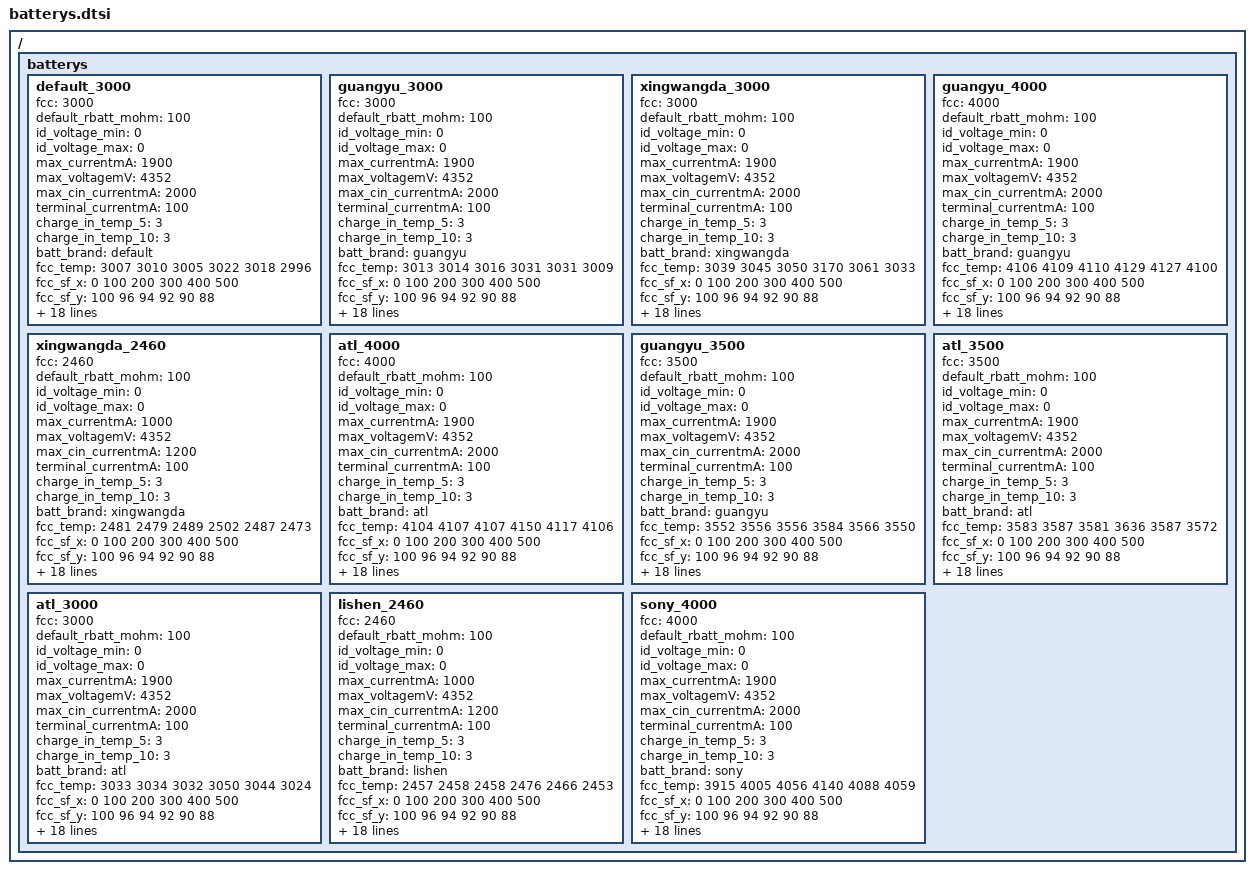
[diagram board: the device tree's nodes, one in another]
/* DO NOT EDIT - Automatically generated by python */
/ {
	batterys:batterys {
		default_3000:default_3000 {
			fcc = <3000>;
			default_rbatt_mohm = <100>;
			id_voltage_min = <0>;
			id_voltage_max = <0>;
			max_currentmA = <1900>;
			max_voltagemV = <4352>;
			max_cin_currentmA = <2000>;
			terminal_currentmA = <100>;
			charge_in_temp_5 = <3>;
			charge_in_temp_10 = <3>;
			batt_brand = "default";
			fcc_temp = <3007 3010 3005 3022 3018 2996>;
			fcc_sf_x = <0 100 200 300 400 500>;
			fcc_sf_y = <100 96 94 92 90 88>;
			fcc_sf_cols = <6>;
			pc_sf_rows = <1>;
			pc_sf_cols = <1>;
			pc_sf_row_entries = <0>;
			pc_sf_percent = <100>;
			pc_sf_sf = <100>;
			rbatt_sf_rows = <28>;
			rbatt_sf_cols = <6>;
			rbatt_sf_percent = <100 95 90 85 80 75 70 65 60 55 50 45 40 35 30 25 20 15 10 9 8 7 6 5 4 3 2 1>;
			rbatt_sf_sf = <
			               1971 888 459 150 121 112
			               1970 888 459 150 121 112
			               1839 913 472 152 123 113
			               1713 920 490 156 125 115
			               1676 943 504 161 128 116
			               1543 895 532 170 132 118
			               1517 837 489 181 137 121
			               1515 831 470 199 148 127
			               1516 824 448 200 160 137
			               1531 823 437 155 129 116
			               1611 847 434 150 123 114
			               1714 921 422 151 124 115
			               1830 1023 448 155 128 117
			               1954 1148 499 158 134 120
			               2083 1284 576 159 132 122
			               2230 1422 664 157 125 114
			               2410 1589 766 154 122 113
			               2657 1792 883 159 123 113
			               3658 1996 983 161 128 117
			               4481 2141 924 161 129 119
			               4966 2392 991 159 127 116
			               5434 2660 1095 166 127 116
			               5970 2933 1229 168 130 118
			               6541 3252 1382 172 129 118
			               7189 3594 1509 175 129 117
			               7980 3994 1669 183 132 119
			               8915 4511 1946 202 136 120
			               10198 5252 2365 279 143 122
			              >;
			pc_temp_ocv_rows = <29>;
			pc_temp_ocv_cols = <6>;
			pc_temp_ocv_percent = <100 95 90 85 80 75 70 65 60 55 50 45 40 35 30 25 20 15 10 9 8 7 6 5 4 3 2 1>;
			pc_temp_ocv_ocv = <
			                   4326 4325 4322 4317 4311 4305
			                   4224 4239 4246 4254 4249 4245
			                   4156 4178 4186 4196 4193 4189
			                   4090 4121 4132 4142 4138 4134
			                   4041 4073 4082 4090 4086 4083
			                   3967 4011 4034 4042 4038 4035
			                   3917 3951 3976 3997 3994 3991
			                   3878 3907 3929 3957 3955 3952
			                   3843 3868 3885 3914 3915 3914
			                   3815 3833 3849 3865 3865 3863
			                   3801 3808 3821 3835 3835 3834
			                   3788 3796 3797 3813 3812 3812
			                   3774 3786 3785 3794 3794 3793
			                   3760 3776 3777 3779 3780 3778
			                   3746 3761 3768 3767 3765 3762
			                   3732 3740 3753 3754 3747 3737
			                   3716 3720 3730 3734 3726 3716
			                   3699 3702 3700 3705 3699 3688
			                   3671 3684 3677 3680 3674 3664
			                   3662 3677 3673 3679 3672 3662
			                   3653 3671 3669 3677 3671 3660
			                   3640 3664 3664 3673 3668 3657
			                   3626 3654 3658 3667 3663 3652
			                   3606 3637 3645 3650 3650 3638
			                   3578 3609 3618 3611 3614 3604
			                   3540 3566 3571 3554 3560 3553
			                   3482 3500 3502 3478 3490 3486
			                   3389 3399 3403 3363 3387 3387
			                   3200 3200 3200 3200 3200 3200
			                  >;
		};
		guangyu_3000:guangyu_3000 {
			fcc = <3000>;
			default_rbatt_mohm = <100>;
			id_voltage_min = <0>;
			id_voltage_max = <0>;
			max_currentmA = <1900>;
			max_voltagemV = <4352>;
			max_cin_currentmA = <2000>;
			terminal_currentmA = <100>;
			charge_in_temp_5 = <3>;
			charge_in_temp_10 = <3>;
			batt_brand = "guangyu";
			fcc_temp = <3013 3014 3016 3031 3031 3009>;
			fcc_sf_x = <0 100 200 300 400 500>;
			fcc_sf_y = <100 96 94 92 90 88>;
			fcc_sf_cols = <6>;
			pc_sf_rows = <1>;
			pc_sf_cols = <1>;
			pc_sf_row_entries = <0>;
			pc_sf_percent = <100>;
			pc_sf_sf = <100>;
			rbatt_sf_rows = <28>;
			rbatt_sf_cols = <6>;
			rbatt_sf_percent = <100 95 90 85 80 75 70 65 60 55 50 45 40 35 30 25 20 15 10 9 8 7 6 5 4 3 2 1>;
			rbatt_sf_sf = <
			               2296 1218 555 154 124 116
			               2295 1218 555 154 124 116
			               2157 1236 570 155 125 116
			               2015 1213 583 159 127 118
			               1974 1232 604 164 130 119
			               1760 1140 645 180 140 121
			               1717 1075 529 180 138 124
			               1715 1101 533 202 149 131
			               1704 1108 532 184 149 133
			               1699 1122 537 153 126 118
			               1762 1161 547 151 124 117
			               1829 1236 555 153 126 118
			               1900 1319 601 158 129 120
			               1981 1414 659 162 134 123
			               2069 1514 725 162 132 119
			               2169 1620 792 159 125 117
			               2287 1768 875 158 125 117
			               2447 1942 988 161 126 118
			               2777 1853 1035 163 129 120
			               3036 1627 929 163 128 120
			               3289 1766 978 160 129 118
			               3533 1910 1057 163 128 120
			               3803 2045 1140 162 127 121
			               4109 2198 1212 160 126 119
			               4433 2395 1256 164 129 119
			               4864 2650 1353 170 130 120
			               5383 2992 1559 182 131 122
			               6090 3480 1878 216 139 127
			              >;
			pc_temp_ocv_rows = <29>;
			pc_temp_ocv_cols = <6>;
			pc_temp_ocv_percent = <100 95 90 85 80 75 70 65 60 55 50 45 40 35 30 25 20 15 10 9 8 7 6 5 4 3 2 1>;
			pc_temp_ocv_ocv = <
			                   4331 4329 4327 4324 4318 4313
			                   4236 4244 4252 4261 4258 4254
			                   4170 4184 4194 4205 4202 4199
			                   4109 4124 4141 4152 4148 4145
			                   4068 4079 4093 4099 4096 4094
			                   3976 4004 4048 4060 4052 4045
			                   3925 3941 3963 3991 3995 4001
			                   3887 3905 3922 3958 3960 3960
			                   3850 3868 3886 3913 3913 3913
			                   3816 3835 3852 3868 3868 3868
			                   3798 3810 3825 3840 3839 3839
			                   3784 3796 3801 3818 3817 3817
			                   3771 3783 3788 3800 3799 3798
			                   3759 3773 3777 3784 3784 3783
			                   3748 3759 3767 3769 3767 3761
			                   3736 3741 3752 3754 3746 3735
			                   3722 3725 3732 3734 3726 3715
			                   3705 3710 3706 3708 3701 3689
			                   3678 3692 3689 3688 3681 3671
			                   3669 3686 3685 3687 3680 3669
			                   3659 3679 3680 3685 3678 3667
			                   3645 3671 3673 3681 3675 3664
			                   3628 3656 3661 3672 3666 3653
			                   3607 3634 3640 3645 3640 3626
			                   3576 3602 3605 3601 3598 3585
			                   3535 3556 3553 3546 3545 3533
			                   3477 3492 3484 3474 3475 3465
			                   3388 3395 3385 3370 3375 3367
			                   3200 3200 3200 3200 3200 3200
			                  >;
		};
		xingwangda_3000:xingwangda_3000 {
			fcc = <3000>;
			default_rbatt_mohm = <100>;
			id_voltage_min = <0>;
			id_voltage_max = <0>;
			max_currentmA = <1900>;
			max_voltagemV = <4352>;
			max_cin_currentmA = <2000>;
			terminal_currentmA = <100>;
			charge_in_temp_5 = <3>;
			charge_in_temp_10 = <3>;
			batt_brand = "xingwangda";
			fcc_temp = <3039 3045 3050 3170 3061 3033>;
			fcc_sf_x = <0 100 200 300 400 500>;
			fcc_sf_y = <100 96 94 92 90 88>;
			fcc_sf_cols = <6>;
			pc_sf_rows = <1>;
			pc_sf_cols = <1>;
			pc_sf_row_entries = <0>;
			pc_sf_percent = <100>;
			pc_sf_sf = <100>;
			rbatt_sf_rows = <28>;
			rbatt_sf_cols = <6>;
			rbatt_sf_percent = <100 95 90 85 80 75 70 65 60 55 50 45 40 35 30 25 20 15 10 9 8 7 6 5 4 3 2 1>;
			rbatt_sf_sf = <
			               2150 1340 721 149 116 105
			               2147 1338 720 149 116 105
			               1947 1200 694 155 120 107
			               1863 1117 674 161 124 111
			               1844 1107 672 167 130 114
			               1812 1106 678 175 135 117
			               1823 1095 677 185 140 120
			               1844 1111 673 199 148 125
			               1880 1123 670 199 154 130
			               1930 1150 678 169 135 116
			               1997 1193 708 154 121 109
			               2076 1251 756 158 126 112
			               2160 1321 818 165 133 116
			               2248 1400 889 172 137 120
			               2345 1483 963 182 135 119
			               2459 1570 1044 188 131 112
			               2618 1661 1125 188 132 111
			               2865 1787 1224 185 134 112
			               6112 2810 1460 197 140 118
			               6697 3079 1592 202 141 117
			               7275 3352 1729 206 143 117
			               7819 3647 1884 213 144 119
			               8352 3959 2048 218 144 120
			               8890 4232 2199 221 148 123
			               9495 4608 2386 238 156 128
			               10120 5012 2622 263 162 125
			               10828 5562 2991 299 167 125
			               11962 6368 3532 500 186 134
			              >;
			pc_temp_ocv_rows = <29>;
			pc_temp_ocv_cols = <6>;
			pc_temp_ocv_percent = <100 95 90 85 80 75 70 65 60 55 50 45 40 35 30 25 20 15 10 9 8 7 6 5 4 3 2 1>;
			pc_temp_ocv_ocv = <
			                   4329 4327 4324 4349 4314 4308
			                   4239 4246 4248 4288 4254 4250
			                   4170 4181 4187 4229 4198 4195
			                   4111 4123 4132 4173 4144 4141
			                   4054 4073 4081 4118 4093 4091
			                   3984 4017 4030 4067 4045 4042
			                   3935 3958 3978 4017 3998 3998
			                   3893 3915 3930 3971 3959 3958
			                   3860 3875 3887 3927 3918 3918
			                   3835 3844 3851 3880 3871 3870
			                   3817 3821 3824 3844 3837 3838
			                   3802 3805 3806 3819 3814 3815
			                   3787 3792 3792 3799 3796 3795
			                   3774 3780 3780 3782 3780 3779
			                   3759 3766 3767 3770 3764 3760
			                   3742 3751 3753 3756 3747 3736
			                   3724 3729 3732 3733 3722 3711
			                   3700 3704 3705 3692 3691 3679
			                   3669 3679 3677 3679 3671 3662
			                   3659 3672 3671 3677 3670 3660
			                   3648 3663 3664 3673 3667 3657
			                   3634 3651 3655 3668 3662 3652
			                   3615 3636 3642 3656 3651 3639
			                   3590 3611 3621 3626 3623 3610
			                   3560 3578 3587 3583 3583 3571
			                   3518 3533 3536 3527 3532 3520
			                   3458 3468 3464 3454 3463 3451
			                   3377 3375 3358 3358 3365 3354
			                   3200 3200 3200 3200 3200 3200
			                  >;
		};
		guangyu_4000:guangyu_4000 {
			fcc = <4000>;
			default_rbatt_mohm = <100>;
			id_voltage_min = <0>;
			id_voltage_max = <0>;
			max_currentmA = <1900>;
			max_voltagemV = <4352>;
			max_cin_currentmA = <2000>;
			terminal_currentmA = <100>;
			charge_in_temp_5 = <3>;
			charge_in_temp_10 = <3>;
			batt_brand = "guangyu";
			fcc_temp = <4106 4109 4110 4129 4127 4100>;
			fcc_sf_x = <0 100 200 300 400 500>;
			fcc_sf_y = <100 96 94 92 90 88>;
			fcc_sf_cols = <6>;
			pc_sf_rows = <1>;
			pc_sf_cols = <1>;
			pc_sf_row_entries = <0>;
			pc_sf_percent = <100>;
			pc_sf_sf = <100>;
			rbatt_sf_rows = <28>;
			rbatt_sf_cols = <6>;
			rbatt_sf_percent = <100 95 90 85 80 75 70 65 60 55 50 45 40 35 30 25 20 15 10 9 8 7 6 5 4 3 2 1>;
			rbatt_sf_sf = <
			               1565 695 344 128 112 107
			               1563 696 344 128 112 107
			               1495 704 349 129 112 108
			               1420 705 353 132 114 108
			               1398 721 361 135 115 109
			               1251 720 400 144 120 111
			               1216 625 342 147 122 113
			               1213 638 332 159 129 117
			               1210 640 332 145 129 119
			               1231 644 322 127 114 108
			               1266 664 322 126 112 108
			               1312 706 330 128 113 108
			               1366 759 342 131 115 110
			               1424 823 368 133 118 113
			               1486 895 401 132 116 111
			               1563 982 441 130 112 108
			               1665 1103 485 130 113 108
			               1802 1289 545 130 114 108
			               2126 1109 434 129 114 112
			               2290 1208 445 130 115 110
			               2430 1312 474 132 116 110
			               2575 1441 511 132 117 114
			               2729 1575 559 133 117 112
			               2869 1704 602 132 115 110
			               3040 1819 649 133 115 110
			               3325 1917 718 135 117 112
			               3667 2016 797 155 119 114
			               4315 2465 877 342 165 133
			              >;
			pc_temp_ocv_rows = <29>;
			pc_temp_ocv_cols = <6>;
			pc_temp_ocv_percent = <100 95 90 85 80 75 70 65 60 55 50 45 40 35 30 25 20 15 10 9 8 7 6 5 4 3 2 1>;
			pc_temp_ocv_ocv = <
			                   4333 4331 4330 4327 4322 4316
			                   4238 4251 4257 4265 4262 4257
			                   4173 4192 4201 4208 4205 4202
			                   4112 4137 4148 4154 4151 4147
			                   4070 4090 4099 4103 4099 4095
			                   3980 4035 4055 4058 4050 4046
			                   3928 3950 3972 3995 3998 4001
			                   3891 3911 3927 3959 3961 3959
			                   3857 3874 3892 3912 3915 3914
			                   3833 3842 3857 3869 3868 3868
			                   3814 3818 3829 3840 3840 3839
			                   3799 3803 3807 3818 3817 3817
			                   3786 3790 3792 3800 3799 3798
			                   3773 3778 3781 3784 3784 3782
			                   3760 3764 3772 3769 3765 3760
			                   3747 3747 3759 3752 3744 3734
			                   3735 3729 3739 3732 3725 3713
			                   3721 3714 3713 3705 3699 3689
			                   3700 3695 3691 3688 3681 3670
			                   3696 3691 3688 3686 3680 3669
			                   3690 3686 3686 3684 3678 3667
			                   3682 3681 3681 3681 3675 3665
			                   3670 3672 3673 3670 3667 3656
			                   3651 3656 3655 3641 3642 3633
			                   3621 3628 3623 3598 3602 3594
			                   3578 3585 3577 3541 3550 3544
			                   3512 3517 3513 3466 3481 3478
			                   3409 3413 3417 3362 3383 3384
			                   3200 3200 3200 3200 3200 3200
			                  >;
		};
		xingwangda_2460:xingwangda_2460 {
			fcc = <2460>;
			default_rbatt_mohm = <100>;
			id_voltage_min = <0>;
			id_voltage_max = <0>;
			max_currentmA = <1000>;
			max_voltagemV = <4352>;
			max_cin_currentmA = <1200>;
			terminal_currentmA = <100>;
			charge_in_temp_5 = <3>;
			charge_in_temp_10 = <3>;
			batt_brand = "xingwangda";
			fcc_temp = <2481 2479 2489 2502 2487 2473>;
			fcc_sf_x = <0 100 200 300 400 500>;
			fcc_sf_y = <100 96 94 92 90 88>;
			fcc_sf_cols = <6>;
			pc_sf_rows = <1>;
			pc_sf_cols = <1>;
			pc_sf_row_entries = <0>;
			pc_sf_percent = <100>;
			pc_sf_sf = <100>;
			rbatt_sf_rows = <28>;
			rbatt_sf_cols = <6>;
			rbatt_sf_percent = <100 95 90 85 80 75 70 65 60 55 50 45 40 35 30 25 20 15 10 9 8 7 6 5 4 3 2 1>;
			rbatt_sf_sf = <
			               3248 2075 1055 235 151 131
			               3247 2075 1055 235 151 131
			               2997 1985 1040 239 153 131
			               2843 1898 1019 243 156 134
			               2704 1860 1050 250 160 136
			               2535 1659 1002 270 167 139
			               2514 1648 908 272 175 143
			               2502 1646 912 297 186 151
			               2503 1647 882 278 206 166
			               2518 1641 880 229 156 135
			               2550 1669 888 224 150 132
			               2601 1701 904 226 153 134
			               2671 1760 953 232 158 137
			               2759 1821 1015 238 164 143
			               2874 1897 1093 240 162 142
			               3026 2005 1172 242 155 135
			               3093 2156 1267 246 153 133
			               1808 2375 1388 251 155 133
			               4307 2722 1511 254 159 136
			               6006 2925 1316 250 163 140
			               6516 3169 1419 252 161 139
			               6828 3408 1524 258 159 138
			               7159 3645 1678 257 158 138
			               7408 3869 1794 257 157 137
			               7625 4088 1812 260 156 136
			               8299 4268 1901 268 159 136
			               9290 4549 2002 292 165 137
			               11334 5087 2295 547 175 168
			              >;
			pc_temp_ocv_rows = <29>;
			pc_temp_ocv_cols = <6>;
			pc_temp_ocv_percent = <100 95 90 85 80 75 70 65 60 55 50 45 40 35 30 25 20 15 10 9 8 7 6 5 4 3 2 1>;
			pc_temp_ocv_ocv = <
			                   4315 4313 4316 4307 4300 4294
			                   4222 4228 4237 4242 4239 4235
			                   4154 4167 4178 4186 4183 4180
			                   4103 4112 4123 4134 4130 4127
			                   4043 4069 4082 4083 4080 4077
			                   3970 3982 4022 4040 4034 4030
			                   3928 3939 3956 3981 3990 3988
			                   3891 3903 3921 3953 3952 3950
			                   3859 3871 3881 3908 3914 3913
			                   3834 3842 3849 3862 3863 3863
			                   3814 3820 3823 3833 3835 3834
			                   3796 3801 3805 3812 3813 3813
			                   3781 3787 3792 3794 3796 3795
			                   3767 3771 3782 3780 3782 3781
			                   3755 3757 3771 3768 3767 3764
			                   3743 3742 3755 3756 3751 3741
			                   3730 3730 3736 3739 3732 3720
			                   3722 3717 3715 3711 3705 3693
			                   3681 3698 3703 3689 3681 3672
			                   3679 3692 3698 3687 3680 3670
			                   3673 3685 3694 3686 3679 3669
			                   3663 3677 3691 3684 3677 3667
			                   3649 3666 3687 3679 3674 3663
			                   3623 3650 3677 3664 3662 3650
			                   3578 3627 3650 3625 3630 3616
			                   3524 3589 3606 3569 3578 3564
			                   3465 3531 3537 3489 3507 3494
			                   3378 3436 3429 3372 3399 3389
			                   3200 3200 3200 3200 3200 3200
			                  >;
		};
		atl_4000:atl_4000 {
			fcc = <4000>;
			default_rbatt_mohm = <100>;
			id_voltage_min = <0>;
			id_voltage_max = <0>;
			max_currentmA = <1900>;
			max_voltagemV = <4352>;
			max_cin_currentmA = <2000>;
			terminal_currentmA = <100>;
			charge_in_temp_5 = <3>;
			charge_in_temp_10 = <3>;
			batt_brand = "atl";
			fcc_temp = <4104 4107 4107 4150 4117 4106>;
			fcc_sf_x = <0 100 200 300 400 500>;
			fcc_sf_y = <100 96 94 92 90 88>;
			fcc_sf_cols = <6>;
			pc_sf_rows = <1>;
			pc_sf_cols = <1>;
			pc_sf_row_entries = <0>;
			pc_sf_percent = <100>;
			pc_sf_sf = <100>;
			rbatt_sf_rows = <28>;
			rbatt_sf_cols = <6>;
			rbatt_sf_percent = <100 95 90 85 80 75 70 65 60 55 50 45 40 35 30 25 20 15 10 9 8 7 6 5 4 3 2 1>;
			rbatt_sf_sf = <
			               1638 779 406 150 124 116
			               1635 780 406 150 124 116
			               1515 790 415 152 124 117
			               1434 791 424 155 127 118
			               1370 791 437 161 129 119
			               1295 741 441 168 131 120
			               1283 732 421 179 137 124
			               1276 722 407 186 145 128
			               1281 709 393 175 152 133
			               1305 718 385 155 136 127
			               1354 746 383 149 125 118
			               1426 798 383 149 126 118
			               1513 870 402 151 128 120
			               1612 957 439 153 131 122
			               1720 1060 495 154 130 122
			               1837 1183 567 153 126 117
			               1986 1320 652 153 125 117
			               2209 1470 771 155 127 118
			               3853 1617 747 153 128 119
			               4241 1726 806 155 128 120
			               4675 1864 894 159 129 121
			               5150 1933 1014 162 131 122
			               5702 2318 1182 166 132 124
			               6282 2789 1350 172 133 123
			               6851 3240 1517 175 133 122
			               7837 3723 1611 182 138 126
			               9114 4367 1702 222 185 176
			               12396 5272 2362 401 262 184
			              >;
			pc_temp_ocv_rows = <29>;
			pc_temp_ocv_cols = <6>;
			pc_temp_ocv_percent = <100 95 90 85 80 75 70 65 60 55 50 45 40 35 30 25 20 15 10 9 8 7 6 5 4 3 2 1>;
			pc_temp_ocv_ocv = <
			                   4324 4323 4321 4323 4312 4308
			                   4218 4233 4241 4255 4247 4244
			                   4144 4167 4179 4197 4189 4187
			                   4083 4109 4124 4142 4134 4132
			                   4021 4056 4073 4090 4083 4080
			                   3953 3990 4020 4041 4035 4032
			                   3908 3943 3968 3996 3991 3989
			                   3870 3899 3922 3953 3952 3949
			                   3840 3858 3880 3907 3912 3911
			                   3819 3827 3846 3865 3866 3867
			                   3805 3808 3817 3835 3833 3832
			                   3794 3796 3797 3811 3811 3809
			                   3782 3786 3785 3793 3793 3791
			                   3771 3774 3776 3778 3778 3776
			                   3758 3760 3766 3766 3763 3758
			                   3742 3743 3751 3753 3746 3736
			                   3725 3726 3728 3734 3727 3715
			                   3708 3709 3698 3702 3697 3686
			                   3689 3687 3670 3678 3671 3661
			                   3683 3682 3666 3676 3669 3659
			                   3676 3678 3662 3673 3667 3657
			                   3669 3664 3659 3668 3663 3653
			                   3661 3653 3655 3661 3658 3648
			                   3643 3639 3647 3644 3644 3634
			                   3600 3613 3626 3608 3611 3599
			                   3545 3567 3581 3551 3558 3547
			                   3476 3500 3504 3475 3491 3482
			                   3375 3398 3408 3370 3396 3383
			                   3200 3200 3200 3200 3200 3200
			                  >;
		};
		guangyu_3500:guangyu_3500 {
			fcc = <3500>;
			default_rbatt_mohm = <100>;
			id_voltage_min = <0>;
			id_voltage_max = <0>;
			max_currentmA = <1900>;
			max_voltagemV = <4352>;
			max_cin_currentmA = <2000>;
			terminal_currentmA = <100>;
			charge_in_temp_5 = <3>;
			charge_in_temp_10 = <3>;
			batt_brand = "guangyu";
			fcc_temp = <3552 3556 3556 3584 3566 3550>;
			fcc_sf_x = <0 100 200 300 400 500>;
			fcc_sf_y = <100 96 94 92 90 88>;
			fcc_sf_cols = <6>;
			pc_sf_rows = <1>;
			pc_sf_cols = <1>;
			pc_sf_row_entries = <0>;
			pc_sf_percent = <100>;
			pc_sf_sf = <100>;
			rbatt_sf_rows = <28>;
			rbatt_sf_cols = <6>;
			rbatt_sf_percent = <100 95 90 85 80 75 70 65 60 55 50 45 40 35 30 25 20 15 10 9 8 7 6 5 4 3 2 1>;
			rbatt_sf_sf = <
			               1818 753 394 139 114 106
			               1817 753 394 139 114 107
			               1741 756 397 139 114 107
			               1650 755 404 140 115 107
			               1620 767 414 144 118 108
			               1443 769 452 152 122 109
			               1395 665 395 153 122 111
			               1392 673 388 169 129 115
			               1380 673 377 164 135 120
			               1389 671 365 137 117 109
			               1428 679 367 132 113 107
			               1475 711 375 133 114 107
			               1528 763 388 135 115 109
			               1587 820 417 138 119 111
			               1650 885 453 138 118 112
			               1722 960 495 135 112 107
			               1808 1050 544 135 113 106
			               1928 1196 603 136 113 106
			               2117 1008 490 136 115 106
			               2269 1063 489 136 115 108
			               2447 1135 511 138 115 109
			               2618 1226 534 138 115 110
			               2825 1335 581 138 116 110
			               3040 1457 626 138 114 108
			               3280 1585 658 140 115 109
			               3585 1742 700 147 117 110
			               4006 1979 790 240 120 109
			               4721 2391 1004 197 186 114
			              >;
			pc_temp_ocv_rows = <29>;
			pc_temp_ocv_cols = <6>;
			pc_temp_ocv_percent = <100 95 90 85 80 75 70 65 60 55 50 45 40 35 30 25 20 15 10 9 8 7 6 5 4 3 2 1>;
			pc_temp_ocv_ocv = <
			                   4329 4328 4325 4323 4317 4312
			                   4239 4251 4253 4260 4255 4252
			                   4176 4195 4197 4204 4199 4196
			                   4118 4143 4146 4150 4145 4142
			                   4078 4097 4099 4099 4094 4091
			                   3987 4044 4053 4055 4048 4043
			                   3934 3958 3973 3991 3994 3999
			                   3898 3921 3932 3959 3960 3958
			                   3863 3886 3896 3916 3918 3917
			                   3836 3854 3860 3870 3870 3869
			                   3820 3826 3832 3841 3840 3839
			                   3806 3808 3811 3818 3818 3817
			                   3793 3795 3794 3801 3800 3798
			                   3780 3784 3784 3786 3785 3783
			                   3766 3773 3775 3772 3769 3765
			                   3752 3759 3763 3756 3747 3736
			                   3738 3739 3745 3737 3728 3716
			                   3721 3718 3719 3712 3703 3692
			                   3698 3696 3694 3690 3682 3671
			                   3691 3692 3691 3688 3681 3670
			                   3683 3687 3688 3686 3679 3668
			                   3672 3682 3683 3683 3676 3665
			                   3657 3673 3676 3674 3669 3656
			                   3636 3656 3659 3650 3647 3633
			                   3603 3625 3626 3609 3607 3594
			                   3557 3576 3575 3555 3556 3543
			                   3491 3508 3507 3489 3488 3475
			                   3393 3411 3410 3383 3392 3376
			                   3200 3200 3200 3200 3200 3200
			                  >;
		};
		atl_3500:atl_3500 {
			fcc = <3500>;
			default_rbatt_mohm = <100>;
			id_voltage_min = <0>;
			id_voltage_max = <0>;
			max_currentmA = <1900>;
			max_voltagemV = <4352>;
			max_cin_currentmA = <2000>;
			terminal_currentmA = <100>;
			charge_in_temp_5 = <3>;
			charge_in_temp_10 = <3>;
			batt_brand = "atl";
			fcc_temp = <3583 3587 3581 3636 3587 3572>;
			fcc_sf_x = <0 100 200 300 400 500>;
			fcc_sf_y = <100 96 94 92 90 88>;
			fcc_sf_cols = <6>;
			pc_sf_rows = <1>;
			pc_sf_cols = <1>;
			pc_sf_row_entries = <0>;
			pc_sf_percent = <100>;
			pc_sf_sf = <100>;
			rbatt_sf_rows = <28>;
			rbatt_sf_cols = <6>;
			rbatt_sf_percent = <100 95 90 85 80 75 70 65 60 55 50 45 40 35 30 25 20 15 10 9 8 7 6 5 4 3 2 1>;
			rbatt_sf_sf = <
			               1689 710 398 142 110 97
			               1686 710 398 142 110 97
			               1567 726 409 146 111 99
			               1463 727 420 150 114 101
			               1438 729 429 157 117 102
			               1339 715 441 167 121 104
			               1323 660 414 177 126 108
			               1323 655 402 188 135 112
			               1319 649 389 175 145 119
			               1336 648 378 146 129 117
			               1388 654 375 140 111 100
			               1455 690 376 142 112 100
			               1538 754 385 144 115 103
			               1637 829 415 146 118 106
			               1751 920 461 147 118 106
			               1889 1026 524 147 113 98
			               2063 1168 604 147 111 98
			               2304 1381 714 148 112 99
			               4047 1630 678 146 113 101
			               4518 1817 729 148 115 102
			               4974 2037 784 152 116 103
			               5527 2281 888 157 117 104
			               6126 2591 1028 166 120 104
			               6817 2948 1196 173 122 105
			               7595 3330 1392 171 122 104
			               8534 3821 1629 186 123 105
			               9862 4511 1987 392 127 109
			               13656 5696 2716 228 239 113
			              >;
			pc_temp_ocv_rows = <29>;
			pc_temp_ocv_cols = <6>;
			pc_temp_ocv_percent = <100 95 90 85 80 75 70 65 60 55 50 45 40 35 30 25 20 15 10 9 8 7 6 5 4 3 2 1>;
			pc_temp_ocv_ocv = <
			                   4329 4328 4323 4329 4312 4308
			                   4231 4244 4247 4261 4249 4245
			                   4158 4181 4187 4203 4191 4189
			                   4091 4125 4131 4147 4136 4134
			                   4042 4072 4079 4094 4084 4082
			                   3969 4016 4026 4044 4036 4034
			                   3921 3954 3970 3997 3992 3990
			                   3881 3912 3926 3955 3953 3951
			                   3844 3874 3886 3910 3914 3913
			                   3816 3841 3851 3866 3869 3870
			                   3800 3813 3823 3836 3833 3833
			                   3786 3796 3801 3813 3811 3810
			                   3773 3785 3785 3794 3793 3792
			                   3759 3774 3776 3779 3778 3777
			                   3746 3760 3767 3766 3765 3761
			                   3731 3743 3755 3754 3749 3738
			                   3716 3722 3735 3737 3730 3717
			                   3696 3702 3705 3707 3699 3689
			                   3669 3679 3675 3680 3673 3662
			                   3662 3673 3671 3678 3671 3660
			                   3651 3668 3666 3674 3668 3658
			                   3640 3660 3661 3670 3665 3654
			                   3625 3651 3654 3664 3659 3649
			                   3606 3637 3642 3649 3646 3636
			                   3578 3610 3617 3615 3615 3602
			                   3536 3567 3573 3561 3563 3550
			                   3480 3500 3504 3499 3491 3480
			                   3389 3405 3410 3389 3395 3378
			                   3200 3200 3200 3200 3200 3200
			                  >;
		};
		atl_3000:atl_3000 {
			fcc = <3000>;
			default_rbatt_mohm = <100>;
			id_voltage_min = <0>;
			id_voltage_max = <0>;
			max_currentmA = <1900>;
			max_voltagemV = <4352>;
			max_cin_currentmA = <2000>;
			terminal_currentmA = <100>;
			charge_in_temp_5 = <3>;
			charge_in_temp_10 = <3>;
			batt_brand = "atl";
			fcc_temp = <3033 3034 3032 3050 3044 3024>;
			fcc_sf_x = <0 100 200 300 400 500>;
			fcc_sf_y = <100 96 94 92 90 88>;
			fcc_sf_cols = <6>;
			pc_sf_rows = <1>;
			pc_sf_cols = <1>;
			pc_sf_row_entries = <0>;
			pc_sf_percent = <100>;
			pc_sf_sf = <100>;
			rbatt_sf_rows = <28>;
			rbatt_sf_cols = <6>;
			rbatt_sf_percent = <100 95 90 85 80 75 70 65 60 55 50 45 40 35 30 25 20 15 10 9 8 7 6 5 4 3 2 1>;
			rbatt_sf_sf = <
			               1945 876 456 149 120 111
			               1943 876 456 149 120 111
			               1816 900 469 151 122 113
			               1692 905 486 156 124 114
			               1658 927 498 161 127 115
			               1524 882 528 171 131 118
			               1500 822 482 182 137 121
			               1498 817 464 200 148 127
			               1498 809 443 198 157 135
			               1515 808 434 156 131 118
			               1594 831 429 150 122 114
			               1696 903 419 151 123 115
			               1811 1002 443 155 127 117
			               1934 1124 492 158 133 120
			               2063 1255 565 159 131 121
			               2209 1393 652 156 124 114
			               2391 1560 750 154 122 113
			               2637 1768 870 159 122 113
			               4010 2024 909 160 126 116
			               4629 2200 906 161 126 116
			               5065 2432 973 159 126 115
			               5531 2680 1073 165 127 116
			               6025 2959 1196 169 129 118
			               6587 3266 1333 172 129 117
			               7217 3599 1471 178 129 118
			               7973 3995 1643 184 133 118
			               8932 4540 1942 261 145 125
			               10221 5278 2367 531 224 177
			              >;
			pc_temp_ocv_rows = <29>;
			pc_temp_ocv_cols = <6>;
			pc_temp_ocv_percent = <100 95 90 85 80 75 70 65 60 55 50 45 40 35 30 25 20 15 10 9 8 7 6 5 4 3 2 1>;
			pc_temp_ocv_ocv = <
			                   4328 4327 4324 4319 4313 4307
			                   4226 4240 4248 4255 4250 4246
			                   4157 4179 4188 4197 4193 4190
			                   4091 4122 4134 4142 4138 4135
			                   4042 4074 4083 4090 4086 4084
			                   3967 4013 4036 4042 4038 4035
			                   3918 3952 3976 3997 3994 3991
			                   3879 3908 3930 3957 3955 3952
			                   3843 3869 3886 3913 3915 3914
			                   3815 3834 3851 3865 3866 3865
			                   3801 3808 3822 3835 3835 3834
			                   3788 3796 3798 3813 3812 3812
			                   3774 3786 3785 3794 3794 3793
			                   3760 3776 3777 3779 3780 3778
			                   3746 3761 3768 3767 3765 3761
			                   3732 3740 3753 3753 3747 3737
			                   3716 3720 3730 3734 3726 3716
			                   3699 3703 3701 3704 3698 3688
			                   3672 3683 3677 3680 3674 3664
			                   3663 3677 3673 3679 3672 3662
			                   3654 3671 3669 3677 3670 3660
			                   3642 3664 3665 3673 3668 3657
			                   3627 3655 3659 3666 3662 3652
			                   3607 3638 3645 3648 3649 3638
			                   3580 3611 3619 3608 3613 3603
			                   3541 3568 3574 3550 3559 3551
			                   3487 3506 3508 3476 3488 3482
			                   3400 3413 3414 3373 3387 3384
			                   3200 3200 3200 3200 3200 3200
			                  >;
		};
		lishen_2460:lishen_2460 {
			fcc = <2460>;
			default_rbatt_mohm = <100>;
			id_voltage_min = <0>;
			id_voltage_max = <0>;
			max_currentmA = <1000>;
			max_voltagemV = <4352>;
			max_cin_currentmA = <1200>;
			terminal_currentmA = <100>;
			charge_in_temp_5 = <3>;
			charge_in_temp_10 = <3>;
			batt_brand = "lishen";
			fcc_temp = <2457 2458 2458 2476 2466 2453>;
			fcc_sf_x = <0 100 200 300 400 500>;
			fcc_sf_y = <100 96 94 92 90 88>;
			fcc_sf_cols = <6>;
			pc_sf_rows = <1>;
			pc_sf_cols = <1>;
			pc_sf_row_entries = <0>;
			pc_sf_percent = <100>;
			pc_sf_sf = <100>;
			rbatt_sf_rows = <28>;
			rbatt_sf_cols = <6>;
			rbatt_sf_percent = <100 95 90 85 80 75 70 65 60 55 50 45 40 35 30 25 20 15 10 9 8 7 6 5 4 3 2 1>;
			rbatt_sf_sf = <
			               2891 1327 617 171 119 105
			               2881 1327 617 171 119 105
			               2809 1328 626 174 120 106
			               2726 1315 633 176 122 107
			               2642 1361 677 183 125 108
			               2415 1216 672 199 130 111
			               2421 1186 601 200 135 113
			               2439 1203 613 225 145 120
			               2456 1210 596 217 158 128
			               2495 1243 598 174 129 112
			               2542 1286 616 167 119 107
			               2595 1343 648 171 121 108
			               2665 1404 689 176 124 109
			               2752 1483 743 178 130 114
			               2864 1594 798 181 130 115
			               3694 1729 867 184 122 107
			               4307 1906 965 185 120 106
			               5031 2127 1141 190 122 106
			               6190 2449 1424 201 125 109
			               6492 2435 1374 197 129 111
			               6856 2533 1336 203 129 113
			               7238 2816 1483 204 128 110
			               7657 3072 1648 209 128 110
			               8124 3387 1803 206 125 109
			               8671 3717 1904 208 127 109
			               9240 4048 2094 222 131 111
			               10101 4579 2418 268 134 113
			               11319 5412 2938 558 172 117
			              >;
			pc_temp_ocv_rows = <29>;
			pc_temp_ocv_cols = <6>;
			pc_temp_ocv_percent = <100 95 90 85 80 75 70 65 60 55 50 45 40 35 30 25 20 15 10 9 8 7 6 5 4 3 2 1>;
			pc_temp_ocv_ocv = <
			                   4323 4323 4320 4316 4310 4305
			                   4230 4236 4241 4250 4247 4244
			                   4163 4173 4181 4193 4190 4187
			                   4107 4118 4128 4139 4136 4133
			                   4051 4077 4088 4089 4086 4083
			                   3966 3992 4021 4048 4041 4037
			                   3924 3940 3957 3986 3995 3994
			                   3891 3905 3924 3958 3957 3955
			                   3861 3870 3884 3913 3917 3916
			                   3837 3842 3851 3867 3870 3870
			                   3817 3820 3825 3837 3839 3839
			                   3799 3804 3806 3815 3816 3816
			                   3783 3790 3793 3798 3798 3797
			                   3768 3778 3783 3782 3783 3782
			                   3755 3767 3772 3770 3768 3765
			                   3746 3753 3758 3758 3751 3741
			                   3730 3736 3741 3740 3732 3720
			                   3708 3714 3720 3710 3704 3692
			                   3685 3694 3694 3688 3681 3672
			                   3680 3689 3688 3686 3679 3669
			                   3672 3683 3683 3685 3678 3668
			                   3662 3677 3678 3682 3676 3666
			                   3647 3668 3672 3675 3672 3661
			                   3626 3654 3660 3654 3656 3644
			                   3598 3629 3633 3612 3621 3606
			                   3555 3586 3589 3555 3568 3555
			                   3496 3522 3523 3477 3499 3485
			                   3406 3424 3424 3370 3396 3383
			                   3200 3200 3200 3200 3200 3200
			                  >;
		};
		sony_4000:sony_4000 {
			fcc = <4000>;
			default_rbatt_mohm = <100>;
			id_voltage_min = <0>;
			id_voltage_max = <0>;
			max_currentmA = <1900>;
			max_voltagemV = <4352>;
			max_cin_currentmA = <2000>;
			terminal_currentmA = <100>;
			charge_in_temp_5 = <3>;
			charge_in_temp_10 = <3>;
			batt_brand = "sony";
			fcc_temp = <3915 4005 4056 4140 4088 4059>;
			fcc_sf_x = <0 100 200 300 400 500>;
			fcc_sf_y = <100 96 94 92 90 88>;
			fcc_sf_cols = <6>;
			pc_sf_rows = <1>;
			pc_sf_cols = <1>;
			pc_sf_row_entries = <0>;
			pc_sf_percent = <100>;
			pc_sf_sf = <100>;
			rbatt_sf_rows = <28>;
			rbatt_sf_cols = <6>;
			rbatt_sf_percent = <100 95 90 85 80 75 70 65 60 55 50 45 40 35 30 25 20 15 10 9 8 7 6 5 4 3 2 1>;
			rbatt_sf_sf = <
			               1185 536 314 158 139 135
			               1185 536 314 158 139 135
			               1201 552 325 162 141 136
			               1192 558 333 166 144 138
			               1216 556 340 172 147 139
			               1195 570 349 180 151 142
			               1185 540 333 191 157 145
			               1200 543 323 195 167 151
			               1217 549 326 178 168 158
			               1250 554 326 161 146 141
			               1283 561 328 160 141 137
			               1328 573 335 162 142 138
			               1387 586 342 165 144 139
			               1468 602 351 168 147 141
			               1567 621 361 169 148 143
			               1709 650 377 166 142 138
			               1950 715 389 163 142 139
			               2375 865 408 163 143 138
			               3790 1146 419 162 144 141
			               4171 976 425 163 145 140
			               3467 1048 437 164 145 142
			               3695 1187 464 168 147 143
			               4430 1362 509 172 148 144
			               5454 1629 567 170 148 142
			               6787 2029 637 168 146 141
			               8996 2620 769 170 148 141
			               15834 3764 1100 177 150 143
			               28518 6623 1667 223 152 146
			              >;
			pc_temp_ocv_rows = <29>;
			pc_temp_ocv_cols = <6>;
			pc_temp_ocv_percent = <100 95 90 85 80 75 70 65 60 55 50 45 40 35 30 25 20 15 10 9 8 7 6 5 4 3 2 1>;
			pc_temp_ocv_ocv = <
			                   4330 4327 4325 4323 4312 4306
			                   4247 4252 4251 4254 4245 4241
			                   4183 4192 4192 4195 4188 4185
			                   4119 4134 4135 4140 4134 4131
			                   4070 4076 4079 4087 4082 4080
			                   4011 4028 4028 4038 4035 4032
			                   3954 3969 3974 3993 3991 3989
			                   3910 3925 3927 3949 3951 3950
			                   3870 3887 3891 3902 3909 3911
			                   3838 3853 3858 3863 3865 3865
			                   3807 3823 3829 3836 3836 3835
			                   3783 3799 3806 3814 3814 3813
			                   3764 3778 3787 3796 3797 3795
			                   3750 3762 3772 3782 3783 3781
			                   3734 3745 3760 3768 3767 3763
			                   3718 3728 3748 3751 3746 3735
			                   3701 3710 3729 3732 3724 3713
			                   3678 3691 3699 3703 3697 3686
			                   3641 3667 3667 3672 3668 3658
			                   3632 3661 3661 3668 3664 3655
			                   3625 3652 3656 3663 3660 3651
			                   3614 3643 3649 3657 3655 3647
			                   3598 3631 3641 3649 3647 3638
			                   3579 3615 3627 3631 3628 3615
			                   3548 3589 3598 3593 3589 3575
			                   3502 3547 3549 3540 3537 3523
			                   3440 3483 3482 3470 3468 3455
			                   3345 3379 3380 3368 3370 3360
			                   3200 3200 3200 3200 3200 3200
			                  >;
		};
	};
};
